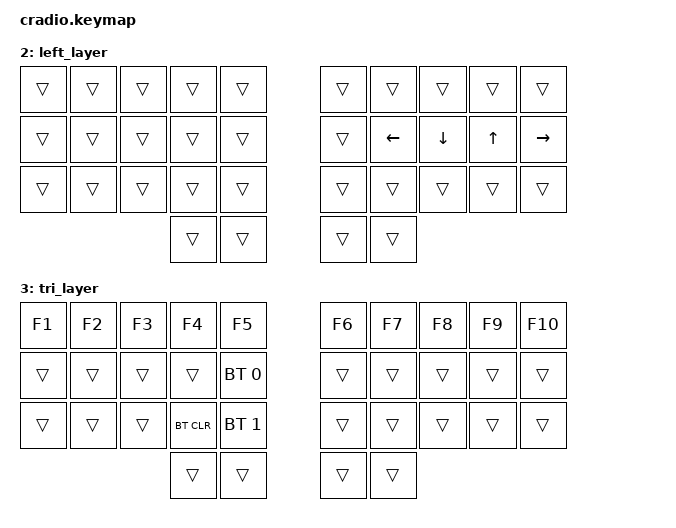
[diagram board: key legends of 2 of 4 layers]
// Copyright (c) 2022 The ZMK Contributors
// SPDX-License-Identifier: MIT

#include <behaviors.dtsi>
#include <dt-bindings/zmk/keys.h>
#include <dt-bindings/zmk/bt.h>

// Home row mods macro
#define HRML(k1,k2,k3,k4) &ht LSHFT k1  &ht LALT k2  &ht LCTRL k3  &ht LGUI k4
#define HRMR(k1,k2,k3,k4) &ht RGUI k1  &ht RCTRL k2  &ht RALT k3  &ht RSHFT k4

/ {
    behaviors {
        ht: hold_tap {
            label = "hold_tap";
            compatible = "zmk,behavior-hold-tap";
            #binding-cells = <2>;
            flavor = "tap-preferred";
            tapping-term-ms = <220>;
            quick-tap-ms = <150>;
            global-quick-tap;
            bindings = <&kp>, <&kp>;
        };
    };

    conditional_layers {
        compatible = "zmk,conditional-layers";
        tri_layer {
            if-layers = <1 2>;
            then-layer = <3>;
        };
    };

    keymap {
        compatible = "zmk,keymap";
        default_layer {
            bindings = <
        //╭──────────┬──────────┬──────────┬──────────┬──────────╮   ╭──────────┬──────────┬──────────┬──────────┬──────────╮
        //│  Q       │  W       │  E       │  R       │  T       │   │  Y       │  U       │  I       │  O       │  P       │
            &kp Q      &kp W      &kp E      &kp R      &kp T          &kp Y      &kp U      &kp I      &kp O      &kp P
        //├──────────┼──────────┼──────────┼──────────┼──────────┤   ├──────────┼──────────┼──────────┼──────────┼──────────┤
        //│  A       │  S       │  D       │  F       │  G       │   │  H       │  J       │  K       │  L       │ ; :      │
            HRML(A,        S,         D,         F)     &kp G          &kp H      HRMR(J,        K,         L,      SEMI)
        //├──────────┼──────────┼──────────┼──────────┼──────────┤   ├──────────┼──────────┼──────────┼──────────┼──────────┤
        //│  Z       │  X       │  C       │  V       │  B       │   │  N       │  M       │ , <      │ . >      │ / ?      │
            &kp Z      &kp X      &kp C      &kp V      &kp B          &kp N      &kp M      &kp COMMA  &kp DOT    &kp FSLH
        //╰──────────┴──────────┴──────────┼──────────┼──────────┤   ├──────────┼──────────┼──────────┴──────────┴──────────╯
                                            &lt 2 TAB   &kp SPACE     &kp BSPC   &lt 1 ENTER
        //                                 ╰──────────┴──────────╯   ╰──────────┴──────────╯
            >;
        };

        right_layer {
            bindings = <
        //╭──────────┬──────────┬──────────┬──────────┬──────────╮   ╭──────────┬──────────┬──────────┬──────────┬──────────╮
        //│  1       │  2       │  3       │  4       │  5       │   │  6       │  7       │  8       │ 9        │  0       │
            &kp N1     &kp N2     &kp N3     &kp N4     &kp N5         &kp N6     &kp N7     &kp N8     &kp N9     &kp N0
        //├──────────┼──────────┼──────────┼──────────┼──────────┤   ├──────────┼──────────┼──────────┼──────────┼──────────┤
        //│  !       │  @       │  #       │  $       │  %       │   │  ^       │  &       │  *       │  (       │  )       │
            HRML(EXCL,    AT,        HASH,      DLLR)   &kp PRCNT      &kp CARET HRMR(AMPS,  ASTRK,     LPAR,      RPAR)
        //├──────────┼──────────┼──────────┼──────────┼──────────┤   ├──────────┼──────────┼──────────┼──────────┼──────────┤
        //│  ` ~     │          │          │          │          │   │  - _     │  = +     │  [ {     │ ] }      │  ' "     │
            &kp GRAVE  &trans     &trans     &trans     &trans         &kp MINUS  &kp EQUAL  &kp LBKT   &kp RBKT   &kp SQT
        //╰──────────┴──────────┴──────────┼──────────┼──────────┤   ├──────────┼──────────┼──────────┴──────────┴──────────╯
                                             &trans     &kp ESC        &trans     &trans
        //                                 ╰──────────┴──────────╯   ╰──────────┴──────────╯
            >;
        };

        left_layer {
            bindings = <
        //╭──────────┬──────────┬──────────┬──────────┬──────────╮   ╭──────────┬──────────┬──────────┬──────────┬──────────╮
        //│          │          │          │          │          │   │          │          │          │          │          │
            &trans     &trans     &trans     &trans     &trans         &trans     &trans     &trans     &trans     &trans   
        //├──────────┼──────────┼──────────┼──────────┼──────────┤   ├──────────┼──────────┼──────────┼──────────┼──────────┤
        //│          │          │          │          │          │   │          │  LEFT    │  DOWN    │  UP      │  RIGHT   │
            &trans     &trans     &trans    &trans      &trans         &trans     &kp LEFT   &kp DOWN   &kp UP     &kp RIGHT
        //├──────────┼──────────┼──────────┼──────────┼──────────┤   ├──────────┼──────────┼──────────┼──────────┼──────────┤
        //│          │          │          │          │          │   │          │          │          │          │          │
            &trans     &trans     &trans     &trans     &trans         &trans     &trans     &trans     &trans     &trans
        //╰──────────┴──────────┴──────────┼──────────┼──────────┤   ├──────────┼──────────┼──────────┴──────────┴──────────╯
                                             &trans     &trans         &trans     &trans
        //                                 ╰──────────┴──────────╯   ╰──────────┴──────────╯
            >;
        };

        tri_layer {
            bindings = <
        //╭──────────┬──────────┬──────────┬──────────┬──────────╮   ╭──────────┬──────────┬──────────┬──────────┬──────────╮
        //│  F1      │  F2      │  F3      │  F4      │  F5      │   │  F6      │  F7      │  F8      │  F9      │  F10     │
            &kp F1     &kp F2     &kp F3     &kp F4     &kp F5         &kp F6     &kp F7     &kp F8     &kp F9     &kp F10
        //├──────────┼──────────┼──────────┼──────────┼──────────┤   ├──────────┼──────────┼──────────┼──────────┼──────────┤
        //│          │          │          │          │PROFILE 0 │   │          │          │          │          │          │
            &trans     &trans     &trans     &trans    &bt BT_SEL 0    &trans     &trans     &trans     &trans     &trans
        //├──────────┼──────────┼──────────┼──────────┼──────────┤   ├──────────┼──────────┼──────────┼──────────┼──────────┤
        //│          │          │          │ CLEAR BT │PROFILE 1 │   │          │          │          │          │          │
            &trans     &trans     &trans    &bt BT_CLR &bt BT_SEL 1    &trans     &trans     &trans     &trans     &trans
        //╰──────────┴──────────┴──────────┼──────────┼──────────┤   ├──────────┼──────────┼──────────┴──────────┴──────────╯
                                             &trans     &trans         &trans     &trans
        //                                 ╰──────────┴──────────╯   ╰──────────┴──────────╯
            >;
        };
    };
};
